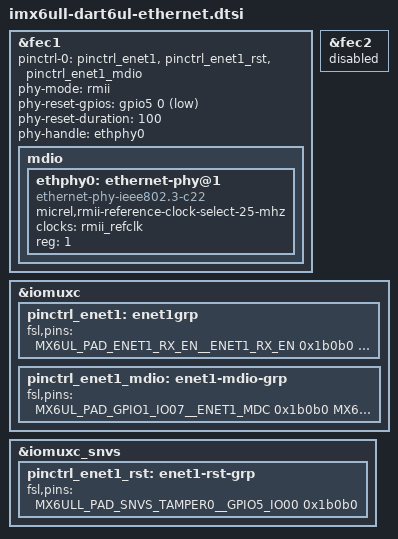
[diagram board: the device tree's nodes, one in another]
/*
 * Copyright (C) 2018 Amotus Solutions, Inc.
 */

&fec1 {
	pinctrl-names = "default";
	pinctrl-0 = <&pinctrl_enet1 &pinctrl_enet1_rst &pinctrl_enet1_mdio>;
	phy-mode = "rmii";
	phy-reset-gpios = <&gpio5 0 GPIO_ACTIVE_LOW>;
	phy-reset-duration = <100>;
	phy-handle = <&ethphy0>;
	status = "okay";

	mdio {
		#address-cells = <1>;
		#size-cells = <0>;

		/* KSZ8081RNB (SoM) */
		ethphy0: ethernet-phy@1 {
			compatible = "ethernet-phy-ieee802.3-c22";
			micrel,rmii-reference-clock-select-25-mhz;
			clocks = <&rmii_refclk>;
			clock-names = "rmii-ref";
			reg = <1>;
		};
	};
};

&fec2 {
	status = "disabled";
};

&iomuxc {
	pinctrl_enet1: enet1grp {
		fsl,pins = <
		MX6UL_PAD_ENET1_RX_EN__ENET1_RX_EN	0x1b0b0
		MX6UL_PAD_ENET1_RX_ER__ENET1_RX_ER	0x1b0b0
		MX6UL_PAD_ENET1_RX_DATA0__ENET1_RDATA00	0x1b0b0
		MX6UL_PAD_ENET1_RX_DATA1__ENET1_RDATA01	0x1b0b0
		MX6UL_PAD_ENET1_TX_EN__ENET1_TX_EN	0x1b0b0
		MX6UL_PAD_ENET1_TX_DATA0__ENET1_TDATA00	0x1b0b0
		MX6UL_PAD_ENET1_TX_DATA1__ENET1_TDATA01	0x1b0b0
		MX6UL_PAD_ENET1_TX_CLK__ENET1_REF_CLK1	0x4001b031
		>;
	};

	pinctrl_enet1_mdio: enet1-mdio-grp {
		fsl,pins = <
		MX6UL_PAD_GPIO1_IO07__ENET1_MDC		0x1b0b0
		MX6UL_PAD_GPIO1_IO06__ENET1_MDIO	0x1b0b0
		>;
	};
};

&iomuxc_snvs {
	pinctrl_enet1_rst: enet1-rst-grp {
		fsl,pins = <
		MX6ULL_PAD_SNVS_TAMPER0__GPIO5_IO00	0x1b0b0
		>;
	};
};
